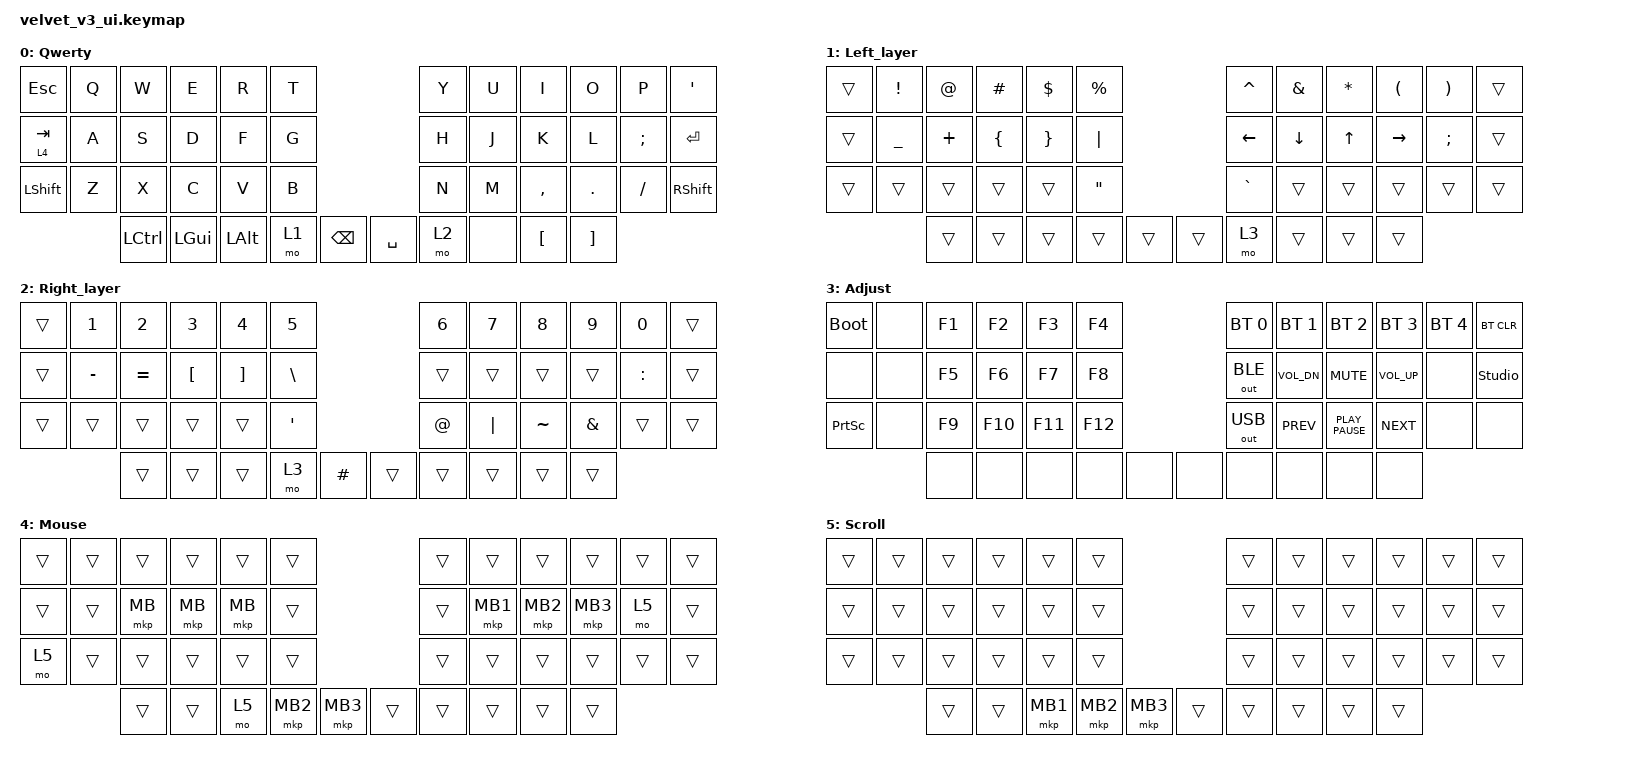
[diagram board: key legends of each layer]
#include "keys_ru.h"
#include <dt-bindings/zmk/input_transform.h>
#include <input/processors.dtsi>
#include <zephyr/dt-bindings/input/input-event-codes.h>
#include <behaviors.dtsi>
#include <dt-bindings/zmk/bt.h>
#include <dt-bindings/zmk/keys.h>
#include <dt-bindings/zmk/outputs.h>
#include <dt-bindings/zmk/pointing.h>

/ {
    behaviors {
        cap_sen: cap_sen {
            compatible = "zmk,behavior-hold-tap";
            label = "CAP_SEN";
            bindings = <&mo>, <&mkp>;

            #binding-cells = <2>;
            tapping-term-ms = <150>;
            hold-while-undecided;
        };

        mouse_layer: mouse_layer {
            compatible = "zmk,behavior-sticky-key";
            label = "MOUSE_LAYER";
            bindings = <&mo>;
            #binding-cells = <1>;
            release-after-ms = <200>;
        };

        zip_auto_mouse: zip_auto_mouse {
            compatible = "zmk,input-processor-temp-layer";
            #input-processor-cells = <2>;
            require-prior-idle-ms = <800>;
            excluded-positions = <>;
        };
    };

    keymap {
        compatible = "zmk,keymap";

        base { 
            bindings = <
&kp ESC    &kp Q  &kp W      &kp E     &kp R      &kp T                          &kp Y  &kp U  &kp I      &kp O    &kp P     &kp SQT
&lt 4 TAB  &kp A  &kp S      &kp D     &kp F      &kp G                          &kp H  &kp J  &kp K      &kp L    &kp SEMI  &kp RET
&kp LSHFT  &kp Z  &kp X      &kp C     &kp V      &kp B                          &kp N  &kp M  &kp COMMA  &kp DOT  &kp FSLH  &kp RSHFT
                  &kp LCTRL  &kp LGUI  &kp LALT   &mo 1  &kp BSPC     &kp SPACE  &mo 2  &none  &kp LBKT   &kp RBKT
            >;

            display-name = "Qwerty";
        };

        left {
            bindings = <
&trans  &kp EXCL   &kp AT    &kp HASH &kp DLLR  &kp PRCNT                     &kp CARET  &kp AMPS  &kp STAR  &kp LPAR   &kp RPAR  &trans
&trans  &kp UNDER  &kp PLUS  &kp LBRC &kp RBRC  &kp PIPE                      &kp LEFT   &kp DOWN  &kp UP    &kp RIGHT  &kp SEMI  &trans
&trans  &trans     &trans    &trans   &trans    &kp DQT                       &kp GRAVE  &trans    &trans    &trans     &trans    &trans
                   &trans    &trans   &trans    &trans     &trans     &trans  &mo 3      &trans    &trans    &trans
            >;

            display-name = "Left_layer";
        };

        right {
            bindings = <
&trans  &kp N1     &kp N2     &kp N3    &kp N4    &kp N5                         &kp N6  &kp N7    &kp N8     &kp N9    &kp N0    &trans
&trans  &kp MINUS  &kp EQUAL  &kp LBKT  &kp RBKT  &kp BSLH                       &trans  &trans    &trans     &trans    &kp COLON &trans
&trans  &trans     &trans     &trans    &trans    &kp SQT                        &kp AT  &kp PIPE  &kp TILDE  &kp AMPS  &trans    &trans
                   &trans     &trans    &trans    &mo 3     &kp HASH     &trans  &trans  &trans    &trans     &trans
            >;

            display-name = "Right_layer";
        };

        adj {
            bindings = <
&bootloader  &none  &kp F1  &kp F2   &kp F3   &kp F4                   &bt BT_SEL 0  &bt BT_SEL 1  &bt BT_SEL 2      &bt BT_SEL 3  &bt BT_SEL 4  &bt BT_CLR
&none        &none  &kp F5  &kp F6   &kp F7   &kp F8                   &out OUT_BLE  &kp C_VOL_DN  &kp K_MUTE        &kp C_VOL_UP  &none         &studio_unlock
&kp PSCRN    &none  &kp F9  &kp F10  &kp F11  &kp F12                  &out OUT_USB  &kp K_PREV    &kp K_PLAY_PAUSE  &kp K_NEXT    &none         &none
                    &none   &none    &none    &none    &none    &none  &none         &none         &none             &none
            >;

            display-name = "Adjust";
        };

        mouse {
            bindings = <
&trans  &trans  &trans     &trans     &trans     &trans                         &trans  &trans    &trans    &trans    &trans  &trans
&trans  &trans  &mkp MB 3  &mkp MB 2  &mkp MB 1  &trans                         &trans  &mkp MB1  &mkp MB2  &mkp MB3  &mo 5   &trans
&mo 5   &trans  &trans     &trans     &trans     &trans                         &trans  &trans    &trans    &trans    &trans  &trans
                &trans     &trans     &mo 5      &mkp MB2  &mkp MB3     &trans  &trans  &trans    &trans    &trans
            >;

            display-name = "Mouse";
        };

        scroll {
            bindings = <
&trans  &trans  &trans  &trans  &trans    &trans                         &trans  &trans  &trans  &trans  &trans  &trans
&trans  &trans  &trans  &trans  &trans    &trans                         &trans  &trans  &trans  &trans  &trans  &trans
&trans  &trans  &trans  &trans  &trans    &trans                         &trans  &trans  &trans  &trans  &trans  &trans
                &trans  &trans  &mkp MB1  &mkp MB2  &mkp MB3     &trans  &trans  &trans  &trans  &trans
            >;

            display-name = "Scroll";
        };
    };
};

&trackball { cpi = <800>; };
